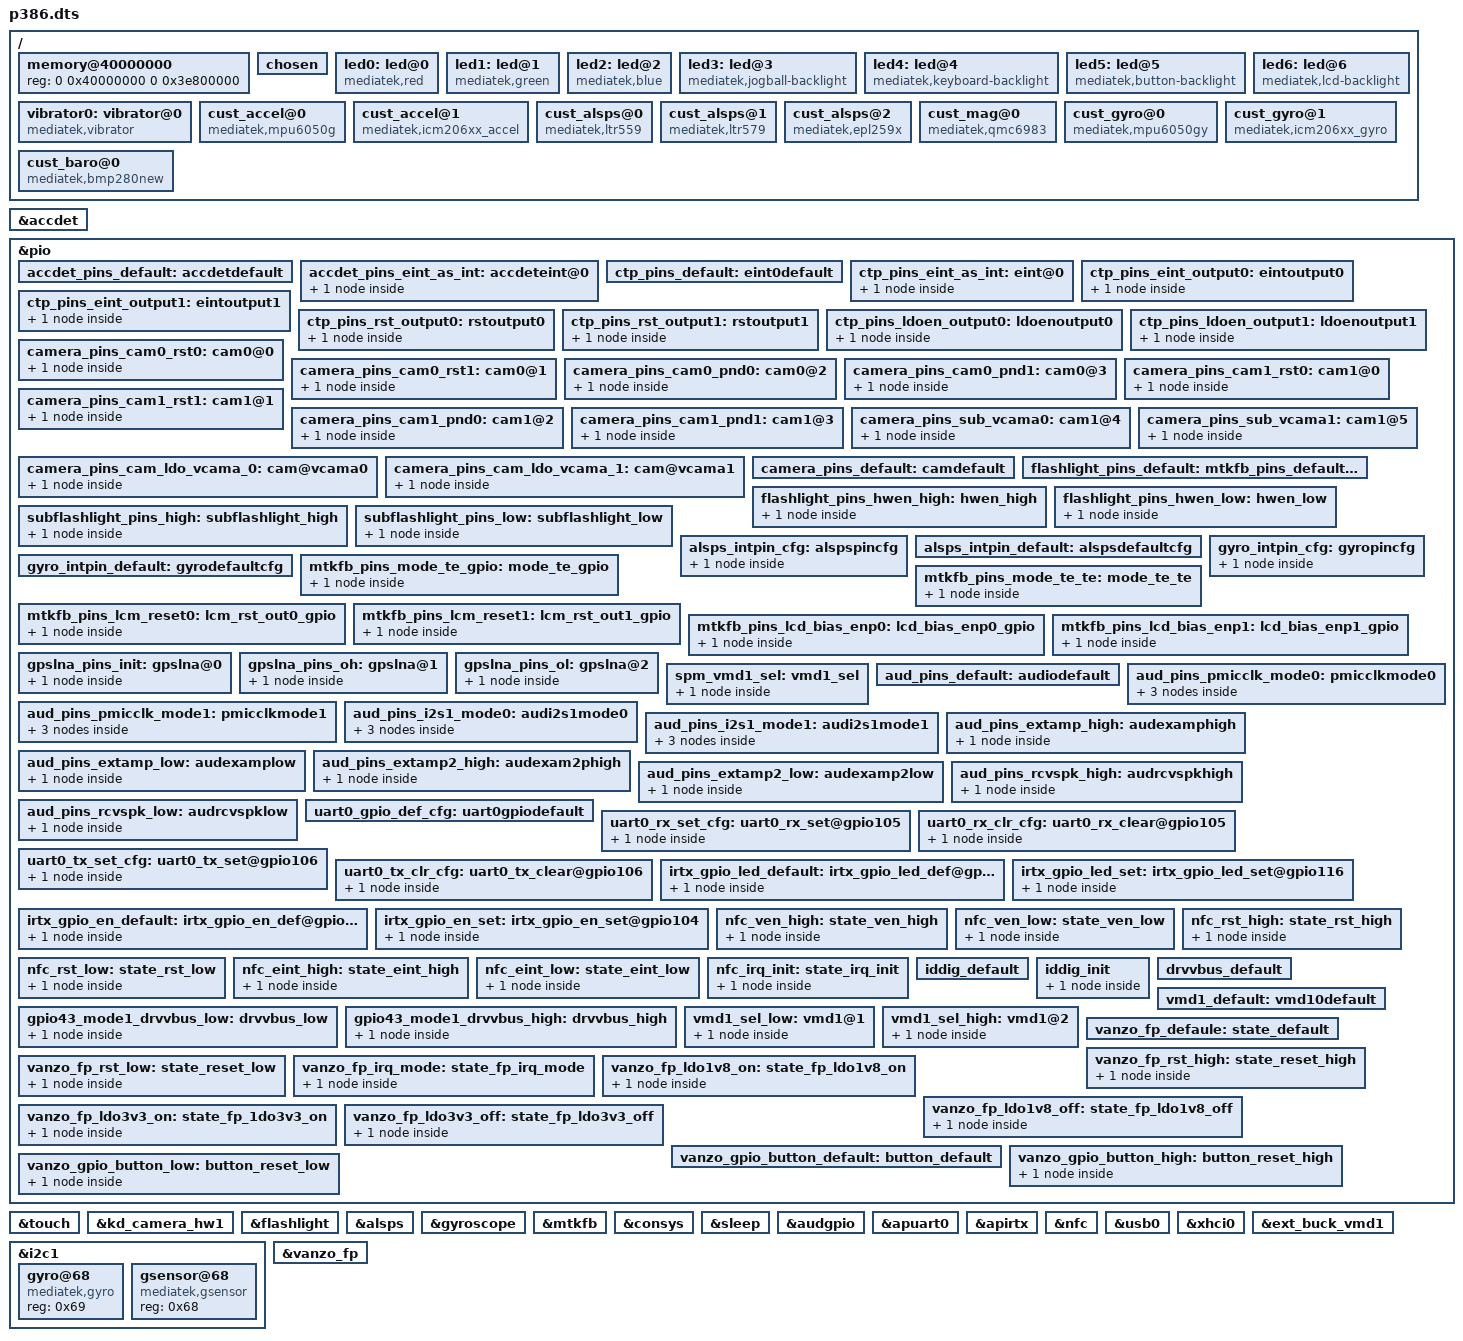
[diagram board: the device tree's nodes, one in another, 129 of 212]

/dts-v1/;

#include "mt6755.dtsi"
#include "cust.dtsi"

/ {
	memory@40000000 {
		device_type = "memory";
		reg = <0 0x40000000 0 0x3e800000>;
	};
	/* chosen */
	chosen {
		bootargs = "console=tty0 console=ttyMT0,921600n1 root=/dev/ram initrd=0x44000000,0x4B434E loglevel=8";

		/* fpga may has no lk, we need to specify display info here */
		/* fb buffer is reserved using this dts by memory node above */
		atag,videolfb-fb_base_h = <0x0>;
		atag,videolfb-fb_base_l = <0x7E800000>;
		atag,videolfb-islcmfound = <1>;
		/* because no lk, so lcm is not inited */
		atag,videolfb-islcm_inited = <0>;
		atag,videolfb-fps= <6000>;
		atag,videolfb-vramSize= <0x01800000>;
		atag,videolfb-lcmname= "nt35695_fhd_dsi_cmd_truly_nt50358_drv";
	};
	led0:led@0 {
		compatible = "mediatek,red";
		led_mode = <3>;
		data = <2>;
		pwm_config = <0 0 0 0 0>;
	};
	led1:led@1 {
		compatible = "mediatek,green";
		led_mode = <3>;
		data = <1>;
		pwm_config = <0 0 0 0 0>;
	};
	led2:led@2 {
		compatible = "mediatek,blue";
		led_mode = <3>;
		data = <3>;
		pwm_config = <0 0 0 0 0>;
	};
	led3:led@3 {
		compatible = "mediatek,jogball-backlight";
		led_mode = <0>;
		data = <1>;
		pwm_config = <0 0 0 0 0>;
	};
	led4:led@4 {
		compatible = "mediatek,keyboard-backlight";
		led_mode = <0>;
		data = <1>;
		pwm_config = <0 0 0 0 0>;
	};
	led5:led@5 {
		compatible = "mediatek,button-backlight";
		led_mode = <2>;
		data = <0>;
		pwm_config = <0 0 0 0 0>;
	};
	led6:led@6 {
		compatible = "mediatek,lcd-backlight";
		led_mode = <5>;
		data = <1>;
		pwm_config = <0 0 0 0 0>;
	};
	vibrator0:vibrator@0 {
		compatible = "mediatek,vibrator";
		vib_timer = <50>;
		vib_limit = <9>;
		vib_vol= <6>;
	};
/*  start sensor */
	cust_accel@0 {
		compatible				= "mediatek,mpu6050g";
		i2c_num					= <1>;
		i2c_addr				= <0x68 0 0 0>;
		direction				= <1>;
		power_id				= <0xffff>;
		power_vol				= <0>;
		firlen					= <0>;
		is_batch_supported		= <0>;
	};
	cust_accel@1 {
		compatible				= "mediatek,icm206xx_accel";
		i2c_num					= <1>;
		i2c_addr				= <0x68 0 0 0>;
		direction				= <3>;
		power_id				= <0xffff>;
		power_vol				= <0>;
		firlen					= <0>;
		is_batch_supported		= <0>;
	};

	cust_alsps@0 {
        compatible = "mediatek,ltr559";
        i2c_num = <1>;
        i2c_addr = <0x23 0 0 0>;
        polling_mode_ps = <0>;
        polling_mode_als = <1>;
        power_id = <0xffff>;
        power_vol = <0>;
        als_level = <10 328 861 1377 3125 7721 7767 12621 23062 28430 33274 47116 57694 57694 65535>;
        als_value = <0 133 304 502 1004 2005 3058 5005 8008 10010 12000 16000 20000 20000 20000 20000>;
        ps_threshold_high               =  <150>;
        ps_threshold_low                =  <100>;
        is_batch_supported_ps   = <0>;
        is_batch_supported_als  = <0>;
	};

    cust_alsps@1 {
         compatible              = "mediatek,ltr579";
         i2c_num                 = <1>;
         i2c_addr                = <0x51 0 0 0>;
         polling_mode_ps         = <0>;
         polling_mode_als        = <1>;
         power_id                = <0xffff>;
         power_vol               = <0>;
         //als_level = <2 100 200 300 400 600 1000 2000 3000 4000 5000 6000 57694 57694 65535>;
         als_level = <2 20 78 240 320 530 900 1200 1400 1700 2000 2500 3000 12694 35535>;
         als_value = <0 133 304 502 1004 2005 3058 5005 8008 10010 12000 16000 20000 20000 20000 20000>;
         ps_threshold_high       = <200>;
         ps_threshold_low        = <100>;
         is_batch_supported_ps   = <0>;
         is_batch_supported_als  = <0>;
     };

		cust_alsps@2 {
		compatible = "mediatek,epl259x";
		i2c_num	= <2>;
		i2c_addr = <0x49>;
		polling_mode_ps = <0>;
		polling_mode_als = <1>;
		power_id = <0xffff>;
		power_vol = <0>;
                als_level  =  <0 400 900 1500 2325 3421 5067 6621 7062 8430 13274 27116 37694 57694 65535>;
                als_value  =  <0 133 304 502 1004 2005 3058 4005 5008 6010 8000 12000 18000 20000 20000 20000>;
		ps_threshold_high		=  <200>;
		ps_threshold_low		=  <100>;
		is_batch_supported_ps	= <0>;
		is_batch_supported_als	= <0>;
		};

	cust_mag@0 {
		compatible				= "mediatek,qmc6983";
		i2c_num					= <1>;
		i2c_addr				= <0x2c 0 0 0>;
		direction				= <2>;
		power_id				= <0xffff>;
		power_vol				= <0>;
		is_batch_supported		= <0>;
	};

	cust_gyro@0 {
		compatible				= "mediatek,mpu6050gy";
		i2c_num					= <1>;
		i2c_addr				= <0x69 0 0 0>;
		direction				= <1>;
		power_id				= <0xffff>;
		power_vol				= <0>;
		firlen					= <0>;
		is_batch_supported		= <0>;
	};
	cust_gyro@1 {
		compatible				= "mediatek,icm206xx_gyro";
		i2c_num					= <1>;
		i2c_addr				= <0x69 0 0 0>;
		direction				= <3>;
		power_id				= <0xffff>;
		power_vol				= <0>;
		firlen					= <0>;
		is_batch_supported		= <0>;
	};

	cust_baro@0 {
	compatible			= "mediatek,bmp280new";
	i2c_num				= <1>;
	/* i2c_addr			= <0x68 0 0 0>; */
	direction			= <0>;
	power_id			= <0xffff>;
	power_vol			= <0>;
	firlen				= <32>;
	is_batch_supported		= <0>;
	};
/* end sensor */
};
/*ACCDET start*/
&accdet {
		accdet-mic-vol = <7>;
		headset-mode-setting = <0x500 0x500 1 0x3F0 0x800 0x800 0x200>;
		accdet-plugout-debounce = <20>;
		/*1:ACC mode, 2:low cost without in bias, 6:low cost with in bias*/
		accdet-mic-mode = <1>;
		/*0--MD_MAX--UP_MAX--DW_MAX*/
		headset-three-key-threshold = <0 80 220 500>;
		/*0--MD_MAX--VOICE_MAX--UP_MAX--DW_MAX*/
		headset-four-key-threshold = <0 59 123 195 450>;
        /* ACCDET GPIO standardization ACC mode use */
        pinctrl-names = "default", "state_eint_as_int";
        pinctrl-0 = <&accdet_pins_default>;
        pinctrl-1 = <&accdet_pins_eint_as_int>;
        status = "okay";
};
&pio {
    accdet_pins_default: accdetdefault {
    };
    accdet_pins_eint_as_int: accdeteint@0 {
        pins_cmd_dat {
            pins = <PINMUX_GPIO2__FUNC_GPIO2>;
            slew-rate = <0>;
            bias-disable;
        };
    };
};
/*ACCDET end*/
/* TOUCH start */
&touch {
	tpd-resolution = <1080 1920>;
	use-tpd-button = <1>;
	tpd-key-num = <3>;
	tpd-key-local= <139 172 158 0>;
	tpd-key-dim-local = <200 2100 100 100 500 2100 100 100 800 2100 100 100 0 0 0 0>;
	tpd-max-touch-num = <5>;
	tpd-filter-enable = <1>;
	tpd-filter-pixel-density = <146>;
	tpd-filter-custom-prameters = <0 0 0 0 0 0 0 0 0 0 0 0>;
	tpd-filter-custom-speed = <0 0 0>;
	pinctrl-names = "default", "state_eint_as_int", "state_eint_output0", "state_eint_output1",
		"state_rst_output0", "state_rst_output1","state_ldoen_output0","state_ldoen_output1";
	pinctrl-0 = <&ctp_pins_default>;
	pinctrl-1 = <&ctp_pins_eint_as_int>;
	pinctrl-2 = <&ctp_pins_eint_output0>;
	pinctrl-3 = <&ctp_pins_eint_output1>;
	pinctrl-4 = <&ctp_pins_rst_output0>;
	pinctrl-5 = <&ctp_pins_rst_output1>;
	pinctrl-6 = <&ctp_pins_ldoen_output0>;
	pinctrl-7 = <&ctp_pins_ldoen_output1>;
	status = "okay";
};
&pio {
	ctp_pins_default: eint0default {
	};
	ctp_pins_eint_as_int: eint@0 {
		pins_cmd_dat {
			pins = <PINMUX_GPIO84__FUNC_GPIO84>;
			slew-rate = <0>;
			bias-disable;
		};
	};
	ctp_pins_eint_output0: eintoutput0 {
		pins_cmd_dat {
			pins = <PINMUX_GPIO84__FUNC_GPIO84>;
			slew-rate = <1>;
			output-low;
		};
	};
	ctp_pins_eint_output1: eintoutput1 {
		pins_cmd_dat {
			pins = <PINMUX_GPIO84__FUNC_GPIO84>;
			slew-rate = <1>;
			output-high;
		};
	};
	ctp_pins_rst_output0: rstoutput0 {
		pins_cmd_dat {
			pins = <PINMUX_GPIO10__FUNC_GPIO10>;
			slew-rate = <1>;
			output-low;
		};
	};
	ctp_pins_rst_output1: rstoutput1 {
		pins_cmd_dat {
			pins = <PINMUX_GPIO10__FUNC_GPIO10>;
			slew-rate = <1>;
			output-high;
		};
	};
	ctp_pins_ldoen_output0: ldoenoutput0 {
		pins_cmd_dat {
			pins = <PINMUX_GPIO20__FUNC_GPIO20>;
			slew-rate = <1>;
			output-low;
		};
	};
	ctp_pins_ldoen_output1: ldoenoutput1 {
		pins_cmd_dat {
			pins = <PINMUX_GPIO20__FUNC_GPIO20>;
			slew-rate = <1>;
			output-high;
		};
	};
};
/* TOUCH end */

/* CAMERA GPIO standardization */
&pio {
	camera_pins_cam0_rst0: cam0@0 {
	    pins_cmd_dat {
			pins = <PINMUX_GPIO110__FUNC_GPIO110>;
			slew-rate = <1>; /*direction 0:in, 1:out*/
			output-low;/*direction out used only. output_low or high*/
		};
	};
	camera_pins_cam0_rst1: cam0@1 {
	    pins_cmd_dat {
			pins = <PINMUX_GPIO110__FUNC_GPIO110>;
			slew-rate = <1>;
			output-high;
		};
	};
	camera_pins_cam0_pnd0: cam0@2 {
	    pins_cmd_dat {
			pins = <PINMUX_GPIO107__FUNC_GPIO107>;
			slew-rate = <1>;
			output-low;
		};
	};
	camera_pins_cam0_pnd1: cam0@3 {
	    pins_cmd_dat {
			pins = <PINMUX_GPIO107__FUNC_GPIO107>;
			slew-rate = <1>;
			output-high;
		};
	};
	camera_pins_cam1_rst0: cam1@0 {
	    pins_cmd_dat {
			pins = <PINMUX_GPIO111__FUNC_GPIO111>;
			slew-rate = <1>; /*direction 0:in, 1:out*/
			output-low;/*direction out used only. output_low or high*/
		};
	};
	camera_pins_cam1_rst1: cam1@1 {
	    pins_cmd_dat {
			pins = <PINMUX_GPIO111__FUNC_GPIO111>;
			slew-rate = <1>;
			output-high;
		};
	};
	camera_pins_cam1_pnd0: cam1@2 {
	    pins_cmd_dat {
			pins = <PINMUX_GPIO108__FUNC_GPIO108>;
			slew-rate = <1>;
			output-low;
		};
	};
	camera_pins_cam1_pnd1: cam1@3 {
	    pins_cmd_dat {
			pins = <PINMUX_GPIO108__FUNC_GPIO108>;
			slew-rate = <1>;
			output-high;
		};
	};
	camera_pins_sub_vcama0: cam1@4 {
		pins_cmd_dat {
			pins = <PINMUX_GPIO19__FUNC_GPIO19>;
			slew-rate = <1>;
			output-low;
		};
	};
	camera_pins_sub_vcama1: cam1@5 {
		pins_cmd_dat {
			pins = <PINMUX_GPIO19__FUNC_GPIO19>;
			slew-rate = <1>;
			output-high;
		};
	};
	camera_pins_cam_ldo_vcama_0: cam@vcama0 {
		pins_cmd_dat {
			pins = <PINMUX_GPIO18__FUNC_GPIO18>;
			slew-rate = <1>;
			output-low;
		};
	};
	camera_pins_cam_ldo_vcama_1: cam@vcama1 {
		pins_cmd_dat {
			pins = <PINMUX_GPIO18__FUNC_GPIO18>;
			slew-rate = <1>;
			output-high;
		};
	};
	camera_pins_default: camdefault {
	};

};

&kd_camera_hw1 {
	pinctrl-names = "default",
			"cam0_rst0", "cam0_rst1", "cam0_pnd0", "cam0_pnd1",
			"cam1_rst0", "cam1_rst1", "cam1_pnd0", "cam1_pnd1",
			"cam_ldo_sub_vcama_0", "cam_ldo_sub_vcama_1",
			/*"cam2_rst0", "cam2_rst1", "cam2_pnd0", "cam2_pnd1",*/
			"cam_ldo_vcama_0", "cam_ldo_vcama_1";
	pinctrl-0 = <&camera_pins_default>;
	pinctrl-1 = <&camera_pins_cam0_rst0>;
	pinctrl-2 = <&camera_pins_cam0_rst1>;
	pinctrl-3 = <&camera_pins_cam0_pnd0>;
	pinctrl-4 = <&camera_pins_cam0_pnd1>;
	pinctrl-5 = <&camera_pins_cam1_rst0>;
	pinctrl-6 = <&camera_pins_cam1_rst1>;
	pinctrl-7 = <&camera_pins_cam1_pnd0>;
	pinctrl-8 = <&camera_pins_cam1_pnd1>;
	pinctrl-9 = <&camera_pins_sub_vcama0>;
	pinctrl-10 = <&camera_pins_sub_vcama1>;
	/* for main2 */
	/*pinctrl-9 = <&camera_pins_cam2_rst0>;
	pinctrl-10 = <&camera_pins_cam2_rst1>;
	pinctrl-11 = <&camera_pins_cam2_pnd0>;
	pinctrl-12 = <&camera_pins_cam2_pnd1>;*/
	/* for ldo control by gpio */
	pinctrl-11 = <&camera_pins_cam_ldo_vcama_0>;
	pinctrl-12 = <&camera_pins_cam_ldo_vcama_1>;
	status = "okay";

};
/* CAMERA GPIO end */
/* FLASHLIGHT GPIO standardization */
&pio {
	flashlight_pins_default: default {
	};

    flashlight_pins_hwen_high: hwen_high {
	    pins_cmd_dat {
            pins = <PINMUX_GPIO8__FUNC_GPIO8>;
			slew-rate = <1>;
			output-high;
		};
	};

    flashlight_pins_hwen_low: hwen_low {
	    pins_cmd_dat {
            pins = <PINMUX_GPIO8__FUNC_GPIO8>;
			slew-rate = <1>;
			output-low;
		};
	};

    subflashlight_pins_high: subflashlight_high {
	    pins_cmd_dat {
            pins = <PINMUX_GPIO0__FUNC_GPIO0>;
			slew-rate = <1>;
			output-high;
		};
	};

    subflashlight_pins_low: subflashlight_low {
	    pins_cmd_dat {
            pins = <PINMUX_GPIO0__FUNC_GPIO0>;
			slew-rate = <1>;
			output-low;
		};
	};
};

&flashlight {
    pinctrl-names = "default", "hwen_high", "hwen_low", "subflashlight_high", "subflashlight_low";
	pinctrl-0 = <&flashlight_pins_default>;
    pinctrl-1 = <&flashlight_pins_hwen_high>;
    pinctrl-2 = <&flashlight_pins_hwen_low>;
    pinctrl-3 = <&subflashlight_pins_high>;
    pinctrl-4 = <&subflashlight_pins_low>;
	status = "okay";
};
/* FLASHLIGHT GPIO standardization  end*/

&pio {
	alsps_intpin_cfg: alspspincfg {

		pins_cmd_dat {
			pins = <PINMUX_GPIO6__FUNC_GPIO6>;
			slew-rate = <0>;
			bias-pull-up = <00>;
		};
	};

	alsps_intpin_default: alspsdefaultcfg {

	};

	gyro_intpin_cfg: gyropincfg {

		pins_cmd_dat {
			pins = <PINMUX_GPIO0__FUNC_GPIO0>;
			slew-rate = <0>;
			bias-pull-down = <00>;
		};
	};

	gyro_intpin_default: gyrodefaultcfg {

	};
};

&alsps {
	pinctrl-names = "pin_default", "pin_cfg";
	pinctrl-0 = <&alsps_intpin_default>;
	pinctrl-1 = <&alsps_intpin_cfg>;
	status = "okay";
};

&gyroscope {
	pinctrl-names = "pin_default", "pin_cfg";
	pinctrl-0 = <&gyro_intpin_default>;
	pinctrl-1 = <&gyro_intpin_cfg>;
	status = "okay";
};

/* DISPSYS GPIO standardization */
&pio {

	mtkfb_pins_mode_te_gpio: mode_te_gpio {
		pins_cmd_dat {
			pins = <PINMUX_GPIO44__FUNC_GPIO44>;
		};
	};

	mtkfb_pins_mode_te_te: mode_te_te {
		pins_cmd_dat {
			pins = <PINMUX_GPIO44__FUNC_DSI_TE>;
		};
	};

	mtkfb_pins_lcm_reset0: lcm_rst_out0_gpio {
		pins_cmd_dat {
			pins = <PINMUX_GPIO158__FUNC_LCM_RST>;
			slew-rate = <1>;
			output-low;
		};
	};

	mtkfb_pins_lcm_reset1: lcm_rst_out1_gpio {
		pins_cmd_dat {
			pins = <PINMUX_GPIO158__FUNC_LCM_RST>;
			slew-rate = <1>;
			output-high;
		};
	};

	mtkfb_pins_lcd_bias_enp0: lcd_bias_enp0_gpio {
		pins_cmd_dat {
			pins = <PINMUX_GPIO22__FUNC_GPIO22>;
			slew-rate = <1>;
			output-low;
		};
	};

	mtkfb_pins_lcd_bias_enp1: lcd_bias_enp1_gpio {
		pins_cmd_dat {
			pins = <PINMUX_GPIO22__FUNC_GPIO22>;
			slew-rate = <1>;
			output-high;
		};
	};

	mtkfb_pins_default: default {
	};
};

&mtkfb {
	pinctrl-names = "default", "mode_te_gpio", "mode_te_te", "lcm_rst_out0_gpio",
	"lcm_rst_out1_gpio", "lcd_bias_enp0_gpio", "lcd_bias_enp1_gpio";
	pinctrl-0 = <&mtkfb_pins_default>;
	pinctrl-1 = <&mtkfb_pins_mode_te_gpio>;
	pinctrl-2 = <&mtkfb_pins_mode_te_te>;
	pinctrl-3 = <&mtkfb_pins_lcm_reset0>;
	pinctrl-4 = <&mtkfb_pins_lcm_reset1>;
	pinctrl-5 = <&mtkfb_pins_lcd_bias_enp0>;
	pinctrl-6 = <&mtkfb_pins_lcd_bias_enp1>;
	status = "okay";
};/* DISPSYS GPIO standardization end */

/* CONSYS GPIO standardization */
&pio {
	consys_pins_default: default {
	};

	gpslna_pins_init: gpslna@0 {
		pins_cmd_dat {
			pins = <PINMUX_GPIO114__FUNC_GPIO114>;
			slew-rate = <0>;
			bias-disable;
			output-low;
		};
	};

	gpslna_pins_oh: gpslna@1 {
		pins_cmd_dat {
			pins = <PINMUX_GPIO114__FUNC_GPIO114>;
			slew-rate = <1>;
			output-high;
		};
	};

	gpslna_pins_ol: gpslna@2 {
		pins_cmd_dat {
			pins = <PINMUX_GPIO114__FUNC_GPIO114>;
			slew-rate = <1>;
			output-low;
		};
	};
};

&consys {
	pinctrl-names = "default", "gps_lna_state_init", "gps_lna_state_oh", "gps_lna_state_ol";
	pinctrl-0 = <&consys_pins_default>;
	pinctrl-1 = <&gpslna_pins_init>;
	pinctrl-2 = <&gpslna_pins_oh>;
	pinctrl-3 = <&gpslna_pins_ol>;
	status = "okay";
};
/* CONSYS end */

/* SPM GPIO standardization */
&pio {
	spm_pins_default: default {
	};

	spm_vmd1_sel: vmd1_sel {
		pins_cmd_dat {
			pins = <PINMUX_GPIO115__FUNC_GPIO115>;
		};
	};

};

&sleep{
	pinctrl-names = "default", "vmd1_sel";
	pinctrl-0 = <&spm_pins_default>;
	pinctrl-1 = <&spm_vmd1_sel>;
	status = "okay";
};
/* SPM end */

/* AUDIO GPIO standardization */
&audgpio {
	pinctrl-names = "default", "audpmicclk-mode0", "audpmicclk-mode1",
		"audi2s1-mode0", "audi2s1-mode1", "extamp-pullhigh", "extamp-pulllow",
		"extamp2-pullhigh", "extamp2-pulllow", "rcvspk-pullhigh",
		"rcvspk-pulllow";
	pinctrl-0 = <&aud_pins_default>;
	pinctrl-1 = <&aud_pins_pmicclk_mode0>;
	pinctrl-2 = <&aud_pins_pmicclk_mode1>;
	pinctrl-3 = <&aud_pins_i2s1_mode0>;
	pinctrl-4 = <&aud_pins_i2s1_mode1>;
	pinctrl-5 = <&aud_pins_extamp_high>;
	pinctrl-6 = <&aud_pins_extamp_low>;
	pinctrl-7 = <&aud_pins_extamp2_high>;
	pinctrl-8 = <&aud_pins_extamp2_low>;
	pinctrl-9 = <&aud_pins_rcvspk_high>;
	pinctrl-10 = <&aud_pins_rcvspk_low>;
	status = "okay";
};

&pio {
	aud_pins_default: audiodefault {
	};

	aud_pins_pmicclk_mode0: pmicclkmode0 {
		pins_cmd0_dat {
			pins = <PINMUX_GPIO149__FUNC_GPIO149>;
		};
		pins_cmd1_dat {
			pins = <PINMUX_GPIO150__FUNC_GPIO150>;
			slew-rate = <0>;
			bias-pull-up = <00>;
		};
		pins_cmd2_dat {
			pins = <PINMUX_GPIO151__FUNC_GPIO151>;
		};
	};

	aud_pins_pmicclk_mode1: pmicclkmode1 {
		pins_cmd0_dat {
			pins = <PINMUX_GPIO149__FUNC_AUD_CLK_MOSI>;
		};
		pins_cmd1_dat {
			pins = <PINMUX_GPIO150__FUNC_AUD_DAT_MOSI>;
		};
		pins_cmd2_dat {
			pins = <PINMUX_GPIO151__FUNC_AUD_DAT_MISO>;
		};
	};

	aud_pins_i2s1_mode0: audi2s1mode0 {
		pins_cmd0_dat {
			pins = <PINMUX_GPIO7__FUNC_GPIO7>;
		};
		pins_cmd1_dat {
			pins = <PINMUX_GPIO6__FUNC_GPIO6>;
		};
		pins_cmd2_dat {
			pins = <PINMUX_GPIO5__FUNC_GPIO5>;
		};
	};

	aud_pins_i2s1_mode1: audi2s1mode1 {
		pins_cmd0_dat {
			pins = <PINMUX_GPIO7__FUNC_I2S0_DI>;
		};
		pins_cmd1_dat {
			pins = <PINMUX_GPIO6__FUNC_I2S0_LRCK>;
		};
		pins_cmd2_dat {
			pins = <PINMUX_GPIO5__FUNC_I2S0_BCK>;
		};
	};

	aud_pins_extamp_high: audexamphigh {
		pins_cmd_dat {
			pins = <PINMUX_GPIO11__FUNC_GPIO11>;
			slew-rate = <1>;
			output-high;
		};
	};

	aud_pins_extamp_low: audexamplow {
		pins_cmd_dat {
			pins = <PINMUX_GPIO11__FUNC_GPIO11>;
			slew-rate = <1>;
			output-low;
		};
	};

	aud_pins_extamp2_high: audexam2phigh {
		pins_cmd_dat {
			pins = <PINMUX_GPIO54__FUNC_GPIO54>;
			slew-rate = <1>;
			output-high;
		};
	};
	aud_pins_extamp2_low: audexamp2low {
		pins_cmd_dat {
			pins = <PINMUX_GPIO54__FUNC_GPIO54>;
			slew-rate = <1>;
			output-low;
		};
	};

	aud_pins_rcvspk_high: audrcvspkhigh {
		pins_cmd_dat {
			pins = <PINMUX_GPIO120__FUNC_GPIO120>;
			slew-rate = <1>;
			output-high;
		};
	};

	aud_pins_rcvspk_low: audrcvspklow {
		pins_cmd_dat {
			pins = <PINMUX_GPIO120__FUNC_GPIO120>;
			slew-rate = <1>;
			output-low;
		};
	};
};
/* AUDIO end */

/* UART GPIO */
&apuart0 {
	pinctrl-names = "uart0_gpio_default",
			"uart0_rx_set",
			"uart0_rx_clear",
			"uart0_tx_set",
			"uart0_tx_clear";
	pinctrl-0 = <&uart0_gpio_def_cfg>;
	pinctrl-1 = <&uart0_rx_set_cfg>;
	pinctrl-2 = <&uart0_rx_clr_cfg>;
	pinctrl-3 = <&uart0_tx_set_cfg>;
	pinctrl-4 = <&uart0_tx_clr_cfg>;
	status = "okay";
};

&pio {
	/* UART GPIO Settings - Start */
	/* UART0: rx set, rx clear, tx clear, tx clear*/
	uart0_gpio_def_cfg:uart0gpiodefault {

	};
	uart0_rx_set_cfg:uart0_rx_set@gpio105 {
		pins_cmd_dat {
			pins = <PINMUX_GPIO105__FUNC_URXD0>;
		};
	};
	uart0_rx_clr_cfg:uart0_rx_clear@gpio105  {
		pins_cmd_dat {
			pins = <PINMUX_GPIO105__FUNC_GPIO105>;
			slew-rate = <1>;
			output-high;
		};
	};
	uart0_tx_set_cfg:uart0_tx_set@gpio106  {
		pins_cmd_dat {
			pins = <PINMUX_GPIO106__FUNC_UTXD0>;
		};
	};
	uart0_tx_clr_cfg:uart0_tx_clear@gpio106  {
		pins_cmd_dat {
			pins = <PINMUX_GPIO106__FUNC_GPIO106>;
			slew-rate = <1>;
			output-high;
		};
	};
};/* UART GPIO end */

/* IRTX GPIO end */
&apirtx {
	pinctrl-names = "irtx_gpio_led_default",
			"irtx_gpio_led_set",
			"irtx_gpio_en_default",
			"irtx_gpio_en_set";

	pinctrl-0 = <&irtx_gpio_led_default>;
	pinctrl-1 = <&irtx_gpio_led_set>;
	pinctrl-2 = <&irtx_gpio_en_default>;
	pinctrl-3 = <&irtx_gpio_en_set>;
	status = "okay";
};
&pio {
	/* IRTX GPIO Settings -Start */
	/* default: GPIO0, output, high */
	irtx_gpio_led_default:irtx_gpio_led_def@gpio116 {
		pins_cmd_dat {
			pins = <PINMUX_GPIO116__FUNC_GPIO116>;
			slew-rate = <1>;
			bias-disable;
			output-low;
			input-schmitt-enable = <0>;
		};
	};

	irtx_gpio_led_set:irtx_gpio_led_set@gpio116 {
		pins_cmd_dat {
			pins = <PINMUX_GPIO116__FUNC_IRTX_OUT>;
			slew-rate = <1>;
			output-high;
		};
	};

	irtx_gpio_en_default:irtx_gpio_en_def@gpio104 {
		pins_cmd_dat {
			pins = <PINMUX_GPIO104__FUNC_GPIO104>;
			slew-rate = <1>;
			bias-disable;
			output-low;
			input-schmitt-enable = <0>;
		};
	};

	irtx_gpio_en_set:irtx_gpio_en_set@gpio104 {
		pins_cmd_dat {
			pins = <PINMUX_GPIO104__FUNC_GPIO104>;
			slew-rate = <1>;
			output-high;
		};
	};


}; /* IRTX GPIO Settings -End */

/* NFC GPIO standardization */
&pio {
	nfc_default: default {

	};

	nfc_ven_high: state_ven_high {
		pins_cmd_dat {
			pins = <PINMUX_GPIO88__FUNC_GPIO88>;
			slew-rate = <1>;
			output-high;
		};
	};

	nfc_ven_low: state_ven_low {
		pins_cmd_dat {
			pins = <PINMUX_GPIO88__FUNC_GPIO88>;
			slew-rate = <1>;
			output-low;
		};
	};

	nfc_rst_high: state_rst_high {
		pins_cmd_dat {
			pins = <PINMUX_GPIO87__FUNC_GPIO87>;
			slew-rate = <1>;
			output-high;
		};
	};

	nfc_rst_low: state_rst_low {
		pins_cmd_dat {
			pins = <PINMUX_GPIO87__FUNC_GPIO87>;
			slew-rate = <1>;
			output-low;
		};
	};

	nfc_eint_high: state_eint_high {
		pins_cmd_dat {
			pins = <PINMUX_GPIO85__FUNC_GPIO85>;
			slew-rate = <1>;
			output-high;
		};
	};

	nfc_eint_low: state_eint_low {
		pins_cmd_dat {
			pins = <PINMUX_GPIO85__FUNC_GPIO85>;
			slew-rate = <1>;
			output-low;
		};
	};

	nfc_irq_init: state_irq_init {
		pins_cmd_dat {
			pins = <PINMUX_GPIO86__FUNC_GPIO86>;
			slew-rate = <0>;
			bias-pull-down = <00>;
		};
	};
};

&nfc {
	pinctrl-names = "default", "ven_high", "ven_low", "rst_high", "rst_low", "eint_high", "eint_low", "irq_init";
	pinctrl-0 = <&nfc_default>;
	pinctrl-1 = <&nfc_ven_high>;
	pinctrl-2 = <&nfc_ven_low>;
	pinctrl-3 = <&nfc_rst_high>;
	pinctrl-4 = <&nfc_rst_low>;
	pinctrl-5 = <&nfc_eint_high>;
	pinctrl-6 = <&nfc_eint_low>;
	pinctrl-7 = <&nfc_irq_init>;
	status = "okay";
};
/* NFC end */




&pio {
	iddig_default: iddig_default {
	};

	iddig_init: iddig_init {
		pins_cmd_dat {
			pins = <PINMUX_GPIO28__FUNC_GPIO28>;
			slew-rate = <0>;
			bias-pull-up = <00>;
		};
	};
};

&pio {
	drvvbus_default: drvvbus_default {
	};

	gpio43_mode1_drvvbus_low: drvvbus_low {
		pins_cmd_dat {
			pins = <PINMUX_GPIO43__FUNC_USB_DRVVBUS>;
			slew-rate = <1>;
			output-low;
		};
	};

	gpio43_mode1_drvvbus_high: drvvbus_high {
		pins_cmd_dat {
			pins = <PINMUX_GPIO43__FUNC_USB_DRVVBUS>;
			slew-rate = <1>;
			output-high;
		};
	};
};

&usb0 {
	pinctrl-names = "iddig_default", "iddig_init";
	pinctrl-0 = <&iddig_default>;
	pinctrl-1 = <&iddig_init>;
	status = "okay";
};

&xhci0 {
	pinctrl-names = "drvvbus_default", "drvvbus_low", "drvvbus_high";
	pinctrl-0 = <&drvvbus_default>;
	pinctrl-1 = <&gpio43_mode1_drvvbus_low>;
	pinctrl-2 = <&gpio43_mode1_drvvbus_high>;
	status = "okay";
};

&i2c1 {

	gyro@68 {
		compatible = "mediatek,gyro";
		reg = <0x69>;
		status = "okay";
	};

	gsensor@68 {
		compatible = "mediatek,gsensor";
		reg = <0x68>;
		status = "okay";
	};
};

&ext_buck_vmd1 {
	pinctrl-names = "default", "vmd1_sel_low", "vmd1_sel_high";

	pinctrl-0 = <&vmd1_default>;
	pinctrl-1 = <&vmd1_sel_low>;
	pinctrl-2 = <&vmd1_sel_high>;
};

&pio {
	vmd1_default: vmd10default {
	};

	vmd1_sel_low: vmd1@1 {
		pins_cmd_dat {
			pins = <PINMUX_GPIO115__FUNC_GPIO115>;
			slew-rate = <1>;
			output-low;
		};
	};

	vmd1_sel_high: vmd1@2 {
		pins_cmd_dat {
			pins = <PINMUX_GPIO115__FUNC_GPIO115>;
			slew-rate = <1>;
			output-high;
		};
	};
};

&pio {
    vanzo_fp_defaule: state_default {

              };
    vanzo_fp_rst_high: state_reset_high{
                    pins_cmd_dat {
                        pins = <PINMUX_GPIO14__FUNC_GPIO14>;
                        slew-rate = <1>;
                        output-high;
                    };
                };
    vanzo_fp_rst_low: state_reset_low{
                   pins_cmd_dat {
                       pins = <PINMUX_GPIO14__FUNC_GPIO14>;
                       slew-rate = <1>;
                       output-low;
                   };
               };
    vanzo_fp_irq_mode: state_fp_irq_mode{
                   pins_cmd_dat {
                       pins = <PINMUX_GPIO24__FUNC_GPIO24>;
                       slew-rate = <0>;
	                   bias-disable;
                   };
               };
    vanzo_fp_ldo1v8_on: state_fp_ldo1v8_on{
                   pins_cmd_dat {
                       pins = <PINMUX_GPIO16__FUNC_GPIO16>;
                       slew-rate = <1>;
                       output-high;
                   };
               };
    vanzo_fp_ldo1v8_off: state_fp_ldo1v8_off{
                   pins_cmd_dat {
                       pins = <PINMUX_GPIO16__FUNC_GPIO16>;
                       slew-rate = <1>;
                       output-low;
                   };
               };
    vanzo_fp_ldo3v3_on: state_fp_1do3v3_on{
                   pins_cmd_dat {
                       pins = <PINMUX_GPIO15__FUNC_GPIO15>;
                       slew-rate = <1>;
                       output-high;
                   };
               };
    vanzo_fp_ldo3v3_off: state_fp_ldo3v3_off{
                   pins_cmd_dat {
                       pins = <PINMUX_GPIO15__FUNC_GPIO15>;
                       slew-rate = <1>;
                       output-low;
                   };
               };
};
&vanzo_fp {
	pinctrl-names = "default", "fp_rst_high", "fp_rst_low","fp_irq_mode","fp_ldo1v8_on","fp_ldo1v8_off","fp_ldo3v3_on","fp_ldo3v3_off";
	pinctrl-0 = <&vanzo_fp_defaule>;
	pinctrl-1 = <&vanzo_fp_rst_high>;
	pinctrl-2 = <&vanzo_fp_rst_low>;
	pinctrl-3 = <&vanzo_fp_irq_mode>;
	pinctrl-4 = <&vanzo_fp_ldo1v8_off>;
	pinctrl-5 = <&vanzo_fp_ldo1v8_on>;
	pinctrl-6 = <&vanzo_fp_ldo3v3_on>;
	pinctrl-7 = <&vanzo_fp_ldo3v3_off>;
    /*&vanzo_fp*/
};
&pio {
    vanzo_gpio_button_default: button_default {

              };
    vanzo_gpio_button_high: button_reset_high{
                    pins_cmd_dat {
                        pins = <PINMUX_GPIO23__FUNC_GPIO23>;
                        slew-rate = <1>;
                        output-high;
                    };
                };
    vanzo_gpio_button_low: button_reset_low{
                   pins_cmd_dat {
                       pins = <PINMUX_GPIO23__FUNC_GPIO23>;
                       slew-rate = <1>;
                       output-low;
                   };
               };
};
&led5 {
	pinctrl-names = "default", "gpio_button_on", "gpio_button_off";
	pinctrl-0 = <&vanzo_gpio_button_default>;
	pinctrl-1 = <&vanzo_gpio_button_high>;
	pinctrl-2 = <&vanzo_gpio_button_low>;
    /*&vanzo_fp*/
};
